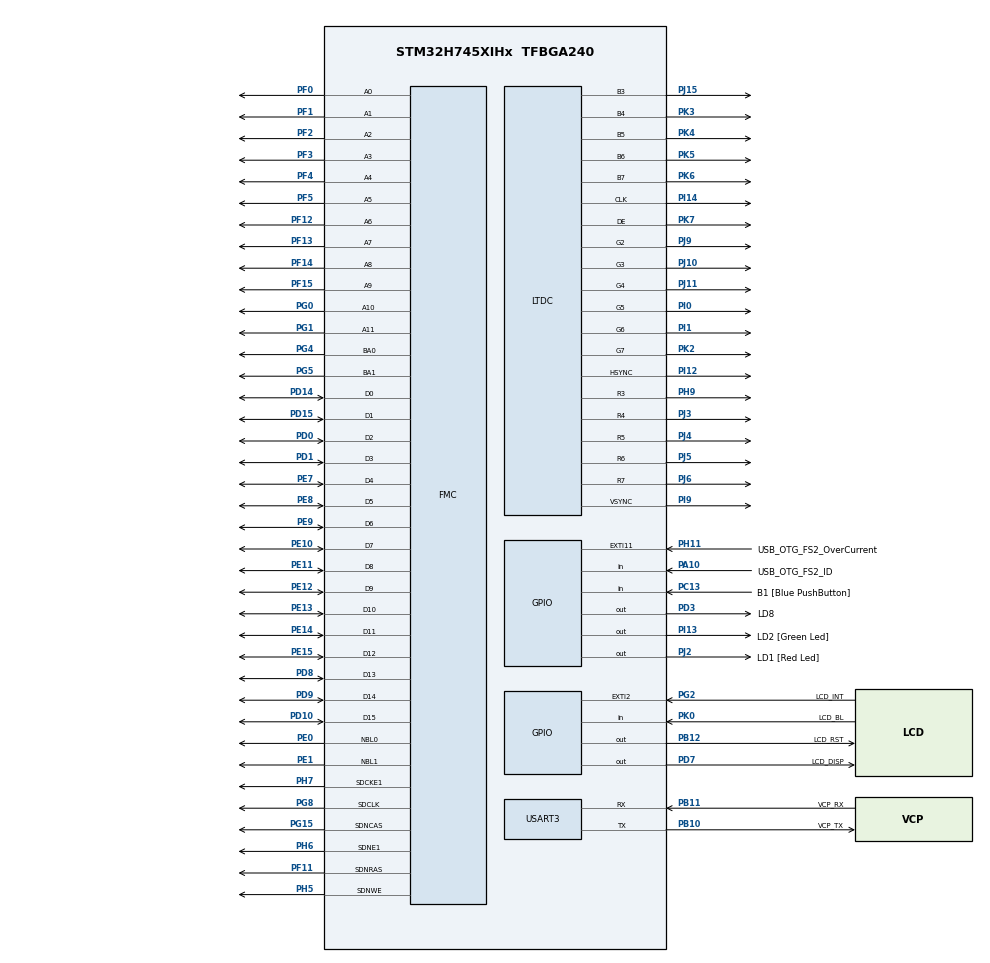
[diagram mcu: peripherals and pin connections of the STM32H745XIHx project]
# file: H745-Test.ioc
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Dma.USART3_RX.0.Polarity=HAL_DMAMUX_REQ_GEN_RISING
FMC.SDClockPeriod2=FMC_SDRAM_CLOCK_PERIOD_2
NVIC1.TimeBaseIP=TIM6
FMC.SDClockPeriod1=FMC_SDRAM_CLOCK_PERIOD_2
SH.FMC_A0.0=FMC_A0,12b-sda1
PH0-OSC_IN\ (PH0).PinAttribute=CortexM7
PI10.PinAttribute=CortexM4
PG8.Signal=FMC_SDCLK
PG0.Signal=FMC_A10
RCC.PLLFRACN=0
Dma.USART3_TX.1.PeriphDataAlignment=DMA_PDATAALIGN_BYTE
Dma.USART3_TX.1.Instance=DMA1_Stream1
SH.FMC_D5_DA5.0=FMC_D5,sd-16b-d1
PB8.PinAttribute=CortexM4
PB6.PinAttribute=CortexM4
SH.FMC_D9_DA9.0=FMC_D9,sd-16b-d1
VP_SYS_M4_VS_tim7.Mode=TIM7
CORTEX_M7.Enable-Cortex_Memory_Protection_Unit_Region0_Settings=MPU_REGION_ENABLE
Dma.USART3_RX.0.MemBurst=DMA_MBURST_SINGLE
PF7.Signal=QUADSPI_BK1_IO2
SH.FMC_SDNWE.0=FMC_SDNWE,12b-sda1
PH9.Signal=LTDC_R3
SH.FMC_D11_DA11.0=FMC_D11,sd-16b-d1
PJ5.Mode=RGB565
PB6.Signal=QUADSPI_BK1_NCS
PC7.Signal=SDMMC1_D7
PD0.Signal=FMC_D2_DA2
PD8.Signal=FMC_D13_DA13
PE1.Signal=FMC_NBL1
PC8.PinAttribute=CortexM4
Dma.USART3_TX.1.SignalID=NONE
PB12.GPIO_Label=LCD_RST
Dma.USART3_RX.0.FIFOThreshold=DMA_FIFO_THRESHOLD_FULL
FMC.SelfRefreshTime1=4
LTDC.PixelFormat_L0=LTDC_PIXEL_FORMAT_RGB565
LTDC.PixelFormat_L1=LTDC_PIXEL_FORMAT_RGB565
PC4.GPIO_Label=MII_RXD0
PE9.Signal=FMC_D6_DA6
SH.FMC_A2.0=FMC_A2,12b-sda1
PD8.PinAttribute=CortexM7
PB1.GPIO_Label=MII_RXD3
PI12.PinAttribute=CortexM7
CortexM7.Pins=PD7,PI13,PJ2
SH.FMC_D1_DA1.0=FMC_D1,sd-16b-d1
LTDC.HSync=41
VP_FREERTOS_M7_VS_CMSIS_V1.Mode=CMSIS_V1
Dma.USART3_TX.1.FIFOMode=DMA_FIFOMODE_DISABLE
PJ14.Signal=LTDC_B2
PA7.PinAttribute=CortexM4
Mcu.Package=TFBGA240
PB9.Signal=SDMMC1_D5
PB1.Signal=ETH_RXD3
VP_FREERTOS_M4_VS_CMSIS_V1.Mode=CMSIS_V1
RCC.PLL3FRACN=0
Dma.USART3_RX.0.PeriphBurst=DMA_PBURST_SINGLE
PA10.Signal=GPIO_Input
Dma.USART3_RX.0.SyncPolarity=HAL_DMAMUX_SYNC_NO_EVENT
FMC.WriteRecoveryTime1=3
PD7.PinAttribute=CortexM7
PC14-OSC32_IN\ (OSC32_IN).Mode=LSE-External-Oscillator
LTDC.VSync=10
FMC.RowCycleDelay2=7
FMC.RowCycleDelay1=7
PD15.Signal=FMC_D1_DA1
PG10.PinAttribute=CortexM4
PC7.PinAttribute=CortexM4
PG12.Signal=ETH_TXD1
PG12.PinAttribute=CortexM4
PK4.Signal=LTDC_B5
SH.FMC_A4.0=FMC_A4,12b-sda1
PH13.Signal=FDCAN1_TX
PA1.PinAttribute=CortexM4
PG5.Signal=FMC_A15_BA1
PC13.Signal=GPIO_Input
SH.FMC_D10_DA10.0=FMC_D10,sd-16b-d1
PD3.Signal=GPIO_Output
PC2.Signal=ETH_TXD2
PF9.PinAttribute=CortexM4
PI12.Signal=LTDC_HSYNC
PE8.PinAttribute=CortexM7
PA9.PinAttribute=CortexM4
RCC.PWR_Regulator_Voltage_Scale=PWR_REGULATOR_VOLTAGE_SCALE1
PG13.PinAttribute=CortexM4
LTDC.ImageWidth_L1=280
PJ11.Signal=LTDC_G4
LTDC.ImageWidth_L0=280
PD10.Signal=FMC_D15_DA15
PJ6.Mode=RGB565
PB8.GPIO_Label=SDIO1_D4
PJ3.Signal=LTDC_R4
PA2.PinAttribute=CortexM4
PH9.Mode=RGB565
PH11.GPIO_Label=USB_OTG_FS2_OverCurrent
Dma.USART3_RX.0.EventEnable=DISABLE
Dma.USART3_RX.0.SyncEnable=DISABLE
PD7.PinState=GPIO_PIN_RESET
PG11.PinAttribute=CortexM4
PB9.PinAttribute=CortexM4
PI7.Signal=SAI2_FS_A
PB1.PinAttribute=CortexM4
FMC.ReadBurst1=FMC_SDRAM_RBURST_ENABLE
SH.FMC_A6.0=FMC_A6,12b-sda1
FMC.ReadBurst2=FMC_SDRAM_RBURST_ENABLE
PE14.Signal=FMC_D11_DA11
LTDC.Blue_L0=0
PA1.GPIO_Label=MII_RX_CLK
PF13.Signal=FMC_A7
PC7.GPIO_Label=SDIO1_D7
PJ15.Mode=RGB565
PC14-OSC32_IN\ (OSC32_IN).GPIO_Label=OSC32_IN
PK4.Mode=RGB565
PC12.GPIO_Label=SDIO1_CK
PJ8.Signal=LTDC_G1
PE9.PinAttribute=CortexM7
ProjectManager.HeapSize=0x200
PH6.Signal=FMC_SDNE1
PD9.PinAttribute=CortexM7
NVIC1.DMA1_Stream0_IRQn=true\:5\:0\:false\:false\:true\:true\:false\:true
PD15.PinAttribute=CortexM7
PJ4.Mode=RGB565
PF4.Signal=FMC_A4
PC9.PinAttribute=CortexM4
Dma.USART3_TX.1.SyncRequestNumber=1
PD2.Signal=SDMMC1_CMD
PC1.PinAttribute=CortexM4
NVIC2.TIM7_IRQn=true\:0\:0\:false\:false\:true\:false\:false\:true
Mcu.Family=STM32H7
LTDC.BlendingFactor1_L1=LTDC_BLENDING_FACTOR1_PAxCA
LTDC.BlendingFactor1_L0=LTDC_BLENDING_FACTOR1_PAxCA
PD2.PinAttribute=CortexM4
PK3.Signal=LTDC_B4
Dma.USART3_RX.0.PeriphInc=DMA_PINC_DISABLE
SH.FMC_A8.0=FMC_A8,12b-sda1
PB10.PinAttribute=CortexM7
PH14.Signal=FDCAN1_RX
SH.FMC_D14_DA14.0=FMC_D14,sd-16b-d1
PH0-OSC_IN\ (PH0).Signal=RCC_OSC_IN
PG2.Signal=GPXTI2
Dma.USART3_TX.1.MemInc=DMA_MINC_ENABLE
PC15-OSC32_OUT\ (OSC32_OUT).Mode=LSE-External-Oscillator
RCC.PLL2FRACN=0
SH.FMC_A14_BA0.0=FMC_BA0,FourSdramBanks1
SH.FMC_A11.0=FMC_A11,12b-sda1
PB13.GPIO_Label=FDCAN2_TX
PC12.PinAttribute=CortexM4
PG11.Signal=ETH_TX_EN
PG15.Signal=FMC_SDNCAS
PG15.PinAttribute=CortexM7
Dma.USART3_TX.1.EventEnable=DISABLE
PJ2.Signal=GPIO_Output
PI9.PinAttribute=CortexM7
PJ2.PinState=GPIO_PIN_SET
LTDC.WindowX1_L1=480
SH.FMC_NBL1.0=FMC_NBL1,Sd2ByteEnable1
LTDC.WindowX1_L0=280
PI9.Mode=RGB565
PE15.PinAttribute=CortexM7
PK2.Mode=RGB565
PH1-OSC_OUT\ (PH1).Mode=HSE-External-Oscillator
FMC.ExitSelfRefreshDelay1=7
Dma.USART3_RX.0.SyncSignalID=NONE
PI14.Mode=RGB565
PB12.PinAttribute=Free
PA13\ (JTMS/SWDIO).PinAttribute=CortexM7
NVIC2.PriorityGroup=NVIC_PRIORITYGROUP_4
PF11.Signal=FMC_SDNRAS
PC11.GPIO_Label=SDIO1_D3
PD14.PinAttribute=CortexM7
LTDC.Red_L1=0
Dma.USART3_RX.0.FIFOMode=DMA_FIFOMODE_ENABLE
CortexM7.IPs=FATFS_M7\:I,FREERTOS_M7\:I,IWDG1\:I,RCC\:I,USB_DEVICE_M7\:I,USB_HOST_M7\:I,WWDG1\:I,DMA\:I,BDMA\:I,MDMA\:I,NVIC1\:I,CORTEX_M7\:I,DEBUG\:I,PDM2PCM_M7\:I,PWR\:I,RESMGR_UTILITY\:I,SYS\:I,OPENAMP_M7\:I,VREFBUF\:I,TIM6\:I,FMC\:I,USART3\:I,LTDC\:I
PD10.PinAttribute=CortexM7
PC10.PinAttribute=CortexM4
PF4.PinAttribute=CortexM7
PI1.Mode=RGB565
PB5.GPIO_Label=FDCAN2_RX
PC3.PinAttribute=CortexM4
Dma.Request1=USART3_TX
PE12.PinAttribute=CortexM7
PG11.GPIO_Label=MII_TX_EN
PD3.GPIO_Label=LD8
PC5.Signal=ETH_RXD1
PE7.Signal=FMC_D4_DA4
Dma.Request0=USART3_RX
PE2.GPIO_Label=MII_TXD3
PG2.GPIO_Label=LCD_INT
PH1-OSC_OUT\ (PH1).PinAttribute=CortexM7
PF15.PinAttribute=CortexM7
PH1-OSC_OUT\ (PH1).GPIO_Label=OSC_OUT
PK6.Signal=LTDC_B7
LTDC.WindowY1_L0=222
LTDC.WindowY1_L1=272
PH13.PinAttribute=CortexM4
PC9.GPIO_Label=SDIO1_D1
Dma.USART3_RX.0.SyncRequestNumber=1
PE10.PinAttribute=CortexM7
PC11.Signal=SDMMC1_D3
PI14.Signal=LTDC_CLK
PI15.PinAttribute=CortexM7
PC8.Signal=SDMMC1_D0
PD9.Signal=FMC_D14_DA14
PE7.PinAttribute=CortexM7
PA12.GPIO_Label=USB_OTG_FS2_P
PJ8.PinAttribute=CortexM7
PH1-OSC_OUT\ (PH1).Signal=RCC_OSC_OUT
PI7.PinAttribute=CortexM4
CORTEX_M7.MPU_Control=MPU_PRIVILEGED_DEFAULT
PI5.PinAttribute=CortexM4
PF10.PinAttribute=CortexM4
PF6.Signal=QUADSPI_BK1_IO3
PC15-OSC32_OUT\ (OSC32_OUT).Signal=RCC_OSC32_OUT
PB10.GPIO_Label=VCP_TX
PI13.PinAttribute=CortexM7
SH.FMC_D13_DA13.0=FMC_D13,sd-16b-d1
RCC.USBFreq_Value=61538461.538461536
PA1.Signal=ETH_RX_CLK
PK0.PinAttribute=Free
PK5.Mode=RGB565
board=STM32H745I-DISCO
PI9.Signal=LTDC_VSYNC
PG5.PinAttribute=CortexM7
PI13.GPIO_Label=LD2 [Green Led]
PK7.PinAttribute=CortexM7
PI4.Signal=SAI2_MCLK_A
NVIC1.CM4_SEV_IRQn=true\:5\:0\:false\:false\:true\:true\:true\:false
RCC.ADCFreq_Value=150000000
PC1.GPIO_Label=MII_MDC
SH.FMC_D12_DA12.0=FMC_D12,sd-16b-d1
PF1.Signal=FMC_A1
NVIC1.TimeBase=TIM6_DAC_IRQn
PJ13.PinAttribute=CortexM7
PJ0.Signal=LTDC_R1
PE0.Signal=FMC_NBL0
PE12.Signal=FMC_D9_DA9
PJ6.PinAttribute=CortexM7
Dma.USART3_RX.0.RequestNumber=1
RCC.SYSCLKFreq_VALUE=400000000
Dma.USART3_RX.0.Priority=DMA_PRIORITY_LOW
PE5.PinAttribute=CortexM4
PC15-OSC32_OUT\ (OSC32_OUT).GPIO_Label=OSC32_OUT
PJ5.Signal=LTDC_R6
PF6.PinAttribute=CortexM4
VP_PWR_V_PVD_IN.Mode=Mode_PVD_Int
PH0-OSC_IN\ (PH0).GPIO_Label=OSC_IN
PH3.Signal=ETH_COL
PC5.PinAttribute=CortexM4
CORTEX_M7.CPU_DCache=Enabled
PJ2.GPIO_Label=LD1 [Red Led]
PH6.PinAttribute=CortexM7
LTDC.ImageHeight_L0=222
LTDC.ImageHeight_L1=222
PB12.Signal=GPIO_Output
PJ13.Signal=LTDC_B1
CortexM4.IPs=FATFS_M4\:I,FREERTOS_M4\:I,IWDG2\:I,RCC,USB_DEVICE_M4\:I,USB_HOST_M4\:I,WWDG2\:I,DMA,BDMA,MDMA,NVIC2\:I,USART3,DEBUG,PDM2PCM_M4\:I,PWR,RESMGR_UTILITY,SYS_M4\:I,CORTEX_M4\:I,OPENAMP_M4\:I,VREFBUF,TIM7\:I
SH.FMC_D7_DA7.0=FMC_D7,sd-16b-d1
PK5.Signal=LTDC_B6
VP_SYS_VS_tim6.Mode=TIM6
PJ9.Mode=RGB565
PD3.PinState=GPIO_PIN_SET
FMC.RCDDelay1=2
PK5.PinAttribute=CortexM7
PB10.Mode=Asynchronous
PG4.Signal=FMC_A14_BA0
PC12.Signal=SDMMC1_CK
FMC.LoadToActiveDelay1=2
PJ4.PinAttribute=CortexM7
PC6.GPIO_Label=SDIO1_D6
PJ3.PinAttribute=CortexM7
PJ11.PinAttribute=CortexM7
PJ12.PinAttribute=CortexM7
Dma.USART3_TX.1.RequestNumber=1
PB13.Signal=FDCAN2_TX
PG13.Signal=ETH_TXD0
RCC.SYSCLKSource=RCC_SYSCLKSOURCE_PLLCLK
PJ10.Signal=LTDC_G3
PI1.PinAttribute=CortexM7
SH.FMC_A15_BA1.0=FMC_BA1,FourSdramBanks1
USART3.VirtualMode-Asynchronous=VM_ASYNC
PA14\ (JTCK/SWCLK).Signal=DEBUG_JTCK-SWCLK
PK6.PinAttribute=CortexM7
PH5.Signal=FMC_SDNWE
PK4.PinAttribute=CortexM7
PI13.PinState=GPIO_PIN_SET
PC3.Signal=ETH_TX_CLK
PE5.Signal=SAI4_CK2
RCC.DIVM3=5
RCC.DIVM2=5
PI4.PinAttribute=CortexM4
RCC.DIVM1=5
PK7.Mode=RGB565
PI6.Signal=SAI2_SD_A
PE2.Signal=ETH_TXD3
PA14\ (JTCK/SWCLK).Mode=Serial_Wire
PJ1.PinAttribute=CortexM7
PJ10.PinAttribute=CortexM7
PF3.Signal=FMC_A3
PJ14.PinAttribute=CortexM7
PJ5.PinAttribute=CortexM7
PE10.Signal=FMC_D7_DA7
RCC.SAI23CLockSelection=RCC_SAI23CLKSOURCE_PLL2
Dma.USART3_TX.1.Priority=DMA_PRIORITY_LOW
PI0.PinAttribute=CortexM7
FREERTOS_M4.Tasks01=defaultTask,0,128,StartDefaultTask,Default,NULL,Dynamic,NULL,NULL
LTDC.Green=127
PJ4.Signal=LTDC_R5
PF0.PinAttribute=CortexM7
SH.FMC_A1.0=FMC_A1,12b-sda1
PH2.Signal=ETH_CRS
SH.FMC_SDCLK.0=FMC_SDCLK,12b-sda1
RCC.APB4Freq_Value=100000000
FREERTOS_M7.Tasks01=defaultTask,0,128,StartDefaultTask,Default,NULL,Dynamic,NULL,NULL
PF14.Signal=FMC_A8
RCC.FDCANCLockSelection=RCC_FDCANCLKSOURCE_PLL2
Dma.USART3_TX.1.PeriphInc=DMA_PINC_DISABLE
PH0-OSC_IN\ (PH0).Mode=HSE-External-Oscillator
SH.FMC_D3_DA3.0=FMC_D3,sd-16b-d1
RCC.SupplySource=PWR_DIRECT_SMPS_SUPPLY
PG0.PinAttribute=CortexM7
PI10.GPIO_Label=MII_RX_ER
Dma.USART3_RX.0.Instance=DMA1_Stream0
Dma.USART3_TX.1.MemDataAlignment=DMA_MDATAALIGN_BYTE
RCC.DIVQ3=13
RCC.DIVQ2=6
RCC.DIVQ1=4
PF1.PinAttribute=CortexM7
Dma.USART3_TX.1.SyncSignalID=NONE
PA9.GPIO_Label=VBUS_FS2
CORTEX_M7.IsCacheable-Cortex_Memory_Protection_Unit_Region0_Settings=MPU_ACCESS_CACHEABLE
PC6.Signal=SDMMC1_D6
PB11.GPIO_Label=VCP_RX
PE0.PinAttribute=CortexM7
PD7.Signal=GPIO_Output
PD1.Signal=FMC_D3_DA3
PA11.GPIO_Label=USB_OTG_FS2_N
RCC.DIVP2=4
PG13.GPIO_Label=MII_TXD0
PJ15.PinAttribute=CortexM7
PG10.Signal=SAI2_SD_B
SH.FMC_A3.0=FMC_A3,12b-sda1
PJ7.Signal=LTDC_G0
PK2.PinAttribute=CortexM7
PA12.PinAttribute=CortexM4
FMC.CASLatency1=FMC_SDRAM_CAS_LATENCY_3
PB11.Mode=Asynchronous
SH.FMC_D15_DA15.0=FMC_D15,sd-16b-d1
PA9.Signal=USB_OTG_FS_VBUS
RCC.DIVN3=160
RCC.DIVN2=120
RCC.DIVN1=160
PH3.PinAttribute=CortexM4
CORTEX_M7.BaseAddress-Cortex_Memory_Protection_Unit_Region0_Settings=0xD0000000
PF12.PinAttribute=CortexM7
PB10.Signal=USART3_TX
RCC.USBCLockSelection=RCC_USBCLKSOURCE_PLL3
PJ15.Signal=LTDC_B3
PG1.PinAttribute=CortexM7
PH6.Mode=SdramChipSelect2_1
PK3.PinAttribute=CortexM7
PH11.PinAttribute=Free
PE15.Signal=FMC_D12_DA12
PA11.PinAttribute=CortexM4
PE8.Signal=FMC_D5_DA5
PI1.Signal=LTDC_G6
PH2.PinAttribute=CortexM4
CORTEX_M7.AccessPermission-Cortex_Memory_Protection_Unit_Region0_Settings=MPU_REGION_FULL_ACCESS
PE1.PinAttribute=CortexM7
SH.FMC_SDNCAS.0=FMC_SDNCAS,12b-sda1
PJ2.PinAttribute=CortexM7
PE2.PinAttribute=CortexM4
PH14.GPIO_Label=FDCAN2_RX
PB5.Signal=FDCAN2_RX
PD11.Signal=QUADSPI_BK1_IO0
LTDC.Alpha_L1=223
SH.FMC_A5.0=FMC_A5,12b-sda1
LTDC.Alpha_L0=255
PA11.Signal=USB_OTG_FS_DM
PD1.PinAttribute=CortexM7
Dma.USART3_TX.1.SyncPolarity=HAL_DMAMUX_SYNC_NO_EVENT
PF2.PinAttribute=CortexM7
PF9.Signal=QUADSPI_BK1_IO1
PJ10.Mode=RGB565
PA14\ (JTCK/SWCLK).PinAttribute=CortexM7
PC3.GPIO_Label=MII_TX_CLK
PE14.PinAttribute=CortexM7
RCC.DIVR3=83
PB0.Signal=ETH_RXD2
PC1.Signal=ETH_MDC
PF13.PinAttribute=CortexM7
PD2.GPIO_Label=SDIO1_CMD
PH2.GPIO_Label=MII_CRS
LTDC.Alpha0_L0=0
PA13\ (JTMS/SWDIO).Signal=DEBUG_JTMS-SWDIO
LTDC.Alpha0_L1=0
PI12.Mode=RGB565
PG2.PinAttribute=Free
PK7.Signal=LTDC_DE
RCC.CortexFreq_Value=400000000
PF5.PinAttribute=CortexM7
RCC.HPRE=RCC_HCLK_DIV2
LTDC.HBP=13
PC10.Signal=SDMMC1_D2
SH.FMC_NBL0.0=FMC_NBL0,Sd2ByteEnable1
SH.FMC_D6_DA6.0=FMC_D6,sd-16b-d1
PB0.GPIO_Label=MII_RXD2
PC13.GPIO_Label=B1 [Blue PushButton]
PB11.Signal=USART3_RX
PC11.PinAttribute=CortexM4
PE4.PinAttribute=CortexM4
ProjectManager.StackSize=0x400
NVIC2.TimeBase=TIM7_IRQn
PJ6.Signal=LTDC_R7
PB11.PinAttribute=CortexM7
SH.FMC_A7.0=FMC_A7,12b-sda1
PA12.Signal=USB_OTG_FS_DP
PA10.PinAttribute=Free
RCC.HCLKFreq_Value=200000000
PH7.PinAttribute=CortexM7
PH9.PinAttribute=CortexM7
PF12.Signal=FMC_A6
PE13.PinAttribute=CortexM7
PI13.Signal=GPIO_Output
PC2.PinAttribute=CortexM4
SH.FMC_A10.0=FMC_A10,12b-sda1
PF14.PinAttribute=CortexM7
PB0.PinAttribute=CortexM4
Dma.USART3_RX.0.MemDataAlignment=DMA_MDATAALIGN_BYTE
SH.FMC_D8_DA8.0=FMC_D8,sd-16b-d1
Dma.USART3_TX.1.Mode=DMA_NORMAL
FMC.RPDelay2=2
FMC.RPDelay1=2
NVIC1.LTDC_IRQn=true\:5\:0\:false\:false\:true\:true\:true\:true
SH.FMC_D2_DA2.0=FMC_D2,sd-16b-d1
PD0.PinAttribute=CortexM7
PE13.Signal=FMC_D10_DA10
PF3.PinAttribute=CortexM7
PI5.Signal=SAI2_SCK_A
PK6.Mode=RGB565
PI0.Signal=LTDC_G5
PA10.GPIO_Label=USB_OTG_FS2_ID
Dma.USART3_RX.0.PeriphDataAlignment=DMA_PDATAALIGN_BYTE
LTDC.HFP=32
LTDC.BlendingFactor2_L0=LTDC_BLENDING_FACTOR2_PAxCA
LTDC.BlendingFactor2_L1=LTDC_BLENDING_FACTOR2_PAxCA
NVIC2.TimeBaseIP=TIM7
SH.FMC_SDNRAS.0=FMC_SDNRAS,12b-sda1
PF7.PinAttribute=CortexM4
LTDC.ActiveW=480
PE4.Signal=SAI4_D2
PD7.GPIO_Label=LCD_DISP
PH7.Mode=SdramChipSelect2_1
RCC.APB3Freq_Value=100000000
Dma.USART3_RX.0.Direction=DMA_PERIPH_TO_MEMORY
PJ9.PinAttribute=CortexM7
PJ9.Signal=LTDC_G2
SH.FMC_D0_DA0.0=FMC_D0,sd-16b-d1
RCC.D1PPRE=RCC_APB3_DIV2
PJ12.Signal=LTDC_B0
PD3.PinAttribute=CortexM4
PK0.GPIO_Label=LCD_BL
PA2.GPIO_Label=MII_MDIO
PG8.PinAttribute=CortexM7
SH.FMC_A9.0=FMC_A9,12b-sda1
PJ1.Signal=LTDC_R2
SH.FMC_D4_DA4.0=FMC_D4,sd-16b-d1
Dma.USART3_RX.0.MemInc=DMA_MINC_ENABLE
PF5.Signal=FMC_A5
PH3.GPIO_Label=MII_COL
PH7.Signal=FMC_SDCKE1
PF0.Signal=FMC_A0
PF11.PinAttribute=CortexM7
PC2.GPIO_Label=MII_TXD2
PG4.PinAttribute=CortexM7
RCC.PLLSourceVirtual=RCC_PLLSOURCE_HSE
PI6.PinAttribute=CortexM4
PK2.Signal=LTDC_G7
LTDC.FBStartAdress_L0=0
CORTEX_M7.CPU_ICache=Enabled
LTDC.FBStartAdress_L1=0
NVIC1.TIM6_DAC_IRQn=true\:0\:0\:false\:false\:true\:false\:false\:true
PA13\ (JTMS/SWDIO).Mode=Serial_Wire
PB9.GPIO_Label=SDIO1_D5
PC10.GPIO_Label=SDIO1_D2
PH11.Signal=GPXTI11
NVIC1.RCC_IRQn=true\:5\:0\:false\:false\:true\:true\:true\:false
PG1.Signal=FMC_A11
CortexM4.Pins=PD3
PJ0.PinAttribute=CortexM7
PI14.PinAttribute=CortexM7
PC4.Signal=ETH_RXD0
NVIC1.PriorityGroup=NVIC_PRIORITYGROUP_4
RCC.D2PPRE2=RCC_APB2_DIV2
RCC.D2PPRE1=RCC_APB1_DIV2
PI10.Signal=ETH_RX_ER
PJ7.PinAttribute=CortexM7
Dma.USART3_RX.0.Mode=DMA_CIRCULAR
PJ11.Mode=RGB565
PB13.PinAttribute=CortexM4
NVIC1.DMA1_Stream1_IRQn=true\:5\:0\:false\:false\:true\:true\:false\:true
PH13.GPIO_Label=FDCAN1_TX
PC8.GPIO_Label=SDIO1_D0
NVIC1.FMC_IRQn=true\:5\:0\:false\:false\:true\:true\:true\:true
ProjectManager.TargetToolchain=STM32CubeIDE
PH14.PinAttribute=CortexM4
LTDC.ActiveH=272
PE11.PinAttribute=CortexM7
PC14-OSC32_IN\ (OSC32_IN).PinAttribute=CortexM7
PI0.Mode=RGB565
PH5.PinAttribute=CortexM7
PF2.Signal=FMC_A2
PC4.PinAttribute=CortexM4
PE11.Signal=FMC_D8_DA8
PK0.Signal=GPIO_Input
NVIC1.USART3_IRQn=true\:5\:0\:false\:false\:true\:true\:true\:true
PC6.PinAttribute=CortexM4
PB5.PinAttribute=CortexM4
PJ3.Mode=RGB565
RCC.APB2Freq_Value=100000000
PF10.Signal=QUADSPI_CLK
PF15.Signal=FMC_A9
PD11.PinAttribute=CortexM4
Mcu.Name=STM32H745XIHx
CORTEX_M7.Size-Cortex_Memory_Protection_Unit_Region0_Settings=MPU_REGION_SIZE_32MB
PA2.Signal=ETH_MDIO
Dma.USART3_TX.1.SyncEnable=DISABLE
PC13.PinAttribute=Free
LTDC.WindowY0_L1=50
PD14.Signal=FMC_D0_DA0
PA7.GPIO_Label=MII_RX_DV
LTDC.WindowX0_L1=200
PC14-OSC32_IN\ (OSC32_IN).Signal=RCC_OSC32_IN
PC5.GPIO_Label=MII_RXD1
Dma.USART3_RX.0.SignalID=NONE
PG12.GPIO_Label=MII_TXD1
Dma.USART3_TX.1.Polarity=HAL_DMAMUX_REQ_GEN_RISING
NVIC2.CM7_SEV_IRQn=true\:5\:0\:false\:false\:true\:true\:true\:false
PK3.Mode=RGB565
Dma.USART3_TX.1.Direction=DMA_MEMORY_TO_PERIPH
PI15.Signal=LTDC_R0
PC15-OSC32_OUT\ (OSC32_OUT).PinAttribute=CortexM7
PB8.Signal=SDMMC1_D4
RCC.D3PPRE=RCC_APB4_DIV2
PC9.Signal=SDMMC1_D1
RCC.APB1Freq_Value=100000000
PA7.Signal=ETH_RX_DV

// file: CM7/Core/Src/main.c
/* USER CODE BEGIN Header */
/**
  ******************************************************************************
  * @file           : main.c
  * @brief          : Main program body
  ******************************************************************************
  * @attention
  *
  * <h2><center>&copy; Copyright (c) 2021 STMicroelectronics.
  * All rights reserved.</center></h2>
  *
  * This software component is licensed by ST under BSD 3-Clause license,
  * the "License"; You may not use this file except in compliance with the
  * License. You may obtain a copy of the License at:
  *                        opensource.org/licenses/BSD-3-Clause
  *
  ******************************************************************************
  */
/* USER CODE END Header */
#include "main.h"
#include "cmsis_os.h"

/* USER CODE BEGIN Includes */
#include "HelloWorld.h"
/* USER CODE END Includes */

/* USER CODE BEGIN PD */

#ifndef HSEM_ID_0
#define HSEM_ID_0 (0U) /* HW semaphore 0*/
#endif
/* USER CODE END PD */

LTDC_HandleTypeDef hltdc;

UART_HandleTypeDef huart3;
DMA_HandleTypeDef hdma_usart3_rx;
DMA_HandleTypeDef hdma_usart3_tx;

SDRAM_HandleTypeDef hsdram1;

osThreadId defaultTaskHandle;
/* USER CODE BEGIN PV */
__IO uint32_t ReloadFlag = 0;
/* Pictures position */
uint32_t Xpos1 = 0;
uint32_t Xpos2 = 200;
uint32_t Ypos1 = 0;
uint32_t Ypos2 = 50;
/* USER CODE END PV */

void SystemClock_Config(void);
static void MPU_Config(void);
static void MX_GPIO_Init(void);
static void MX_DMA_Init(void);
static void MX_FMC_Init(void);
static void MX_USART3_UART_Init(void);
static void MX_LTDC_Init(void);
void StartDefaultTask(void const * argument);

int main(void)
{
/* USER CODE BEGIN Boot_Mode_Sequence_0 */
  int32_t timeout;
/* USER CODE END Boot_Mode_Sequence_0 */

  /* MPU Configuration--------------------------------------------------------*/
  MPU_Config();

  /* Enable I-Cache---------------------------------------------------------*/
  SCB_EnableICache();

  /* Enable D-Cache---------------------------------------------------------*/
  SCB_EnableDCache();

/* USER CODE BEGIN Boot_Mode_Sequence_1 */
  /* Wait until CPU2 boots and enters in stop mode or timeout*/
  timeout = 0xFFFF;
  while((__HAL_RCC_GET_FLAG(RCC_FLAG_D2CKRDY) != RESET) && (timeout-- > 0));
  if ( timeout < 0 )
  {
  Error_Handler();
  }
/* USER CODE END Boot_Mode_Sequence_1 */
  /* MCU Configuration--------------------------------------------------------*/

  /* Reset of all peripherals, Initializes the Flash interface and the Systick. */
  HAL_Init();

  /* Configure the system clock */
  SystemClock_Config();
/* USER CODE BEGIN Boot_Mode_Sequence_2 */
/* When system initialization is finished, Cortex-M7 will release Cortex-M4 by means of
HSEM notification */
/*HW semaphore Clock enable*/
__HAL_RCC_HSEM_CLK_ENABLE();
/*Take HSEM */
HAL_HSEM_FastTake(HSEM_ID_0);
/*Release HSEM in order to notify the CPU2(CM4)*/
HAL_HSEM_Release(HSEM_ID_0,0);
/* wait until CPU2 wakes up from stop mode */
timeout = 0xFFFF;
while((__HAL_RCC_GET_FLAG(RCC_FLAG_D2CKRDY) == RESET) && (timeout-- > 0));
if ( timeout < 0 )
{
Error_Handler();
}
/* USER CODE END Boot_Mode_Sequence_2 */

  /* Initialize all configured peripherals */
  MX_GPIO_Init();
  MX_DMA_Init();
  MX_FMC_Init();
  MX_USART3_UART_Init();
  MX_LTDC_Init();

  /* Create the thread(s) */
  /* definition and creation of defaultTask */
  osThreadDef(defaultTask, StartDefaultTask, osPriorityNormal, 0, 128);
  defaultTaskHandle = osThreadCreate(osThread(defaultTask), NULL);

  /* Start scheduler */
  osKernelStart();

  /* We should never get here as control is now taken by the scheduler */
  /* Infinite loop */
  while (1)
  {

  }
}

void SystemClock_Config(void)
{
  RCC_OscInitTypeDef RCC_OscInitStruct = {0};
  RCC_ClkInitTypeDef RCC_ClkInitStruct = {0};

  /** Supply configuration update enable
  */
  HAL_PWREx_ConfigSupply(PWR_DIRECT_SMPS_SUPPLY);
  /** Configure the main internal regulator output voltage
  */
  __HAL_PWR_VOLTAGESCALING_CONFIG(PWR_REGULATOR_VOLTAGE_SCALE1);

  while(!__HAL_PWR_GET_FLAG(PWR_FLAG_VOSRDY)) {}
  /** Macro to configure the PLL clock source
  */
  __HAL_RCC_PLL_PLLSOURCE_CONFIG(RCC_PLLSOURCE_HSE);
  /** Initializes the RCC Oscillators according to the specified parameters
  * in the RCC_OscInitTypeDef structure.
  */
  RCC_OscInitStruct.OscillatorType = RCC_OSCILLATORTYPE_HSE;
  RCC_OscInitStruct.HSEState = RCC_HSE_ON;
  RCC_OscInitStruct.PLL.PLLState = RCC_PLL_ON;
  RCC_OscInitStruct.PLL.PLLSource = RCC_PLLSOURCE_HSE;
  RCC_OscInitStruct.PLL.PLLM = 5;
  RCC_OscInitStruct.PLL.PLLN = 160;
  RCC_OscInitStruct.PLL.PLLP = 2;
  RCC_OscInitStruct.PLL.PLLQ = 4;
  RCC_OscInitStruct.PLL.PLLR = 2;
  RCC_OscInitStruct.PLL.PLLRGE = RCC_PLL1VCIRANGE_2;
  RCC_OscInitStruct.PLL.PLLVCOSEL = RCC_PLL1VCOWIDE;
  RCC_OscInitStruct.PLL.PLLFRACN = 0;
  if (HAL_RCC_OscConfig(&RCC_OscInitStruct) != HAL_OK)
  {
    Error_Handler();
  }
  /** Initializes the CPU, AHB and APB buses clocks
  */
  RCC_ClkInitStruct.ClockType = RCC_CLOCKTYPE_HCLK|RCC_CLOCKTYPE_SYSCLK
                              |RCC_CLOCKTYPE_PCLK1|RCC_CLOCKTYPE_PCLK2
                              |RCC_CLOCKTYPE_D3PCLK1|RCC_CLOCKTYPE_D1PCLK1;
  RCC_ClkInitStruct.SYSCLKSource = RCC_SYSCLKSOURCE_PLLCLK;
  RCC_ClkInitStruct.SYSCLKDivider = RCC_SYSCLK_DIV1;
  RCC_ClkInitStruct.AHBCLKDivider = RCC_HCLK_DIV2;
  RCC_ClkInitStruct.APB3CLKDivider = RCC_APB3_DIV2;
  RCC_ClkInitStruct.APB1CLKDivider = RCC_APB1_DIV2;
  RCC_ClkInitStruct.APB2CLKDivider = RCC_APB2_DIV2;
  RCC_ClkInitStruct.APB4CLKDivider = RCC_APB4_DIV2;

  if (HAL_RCC_ClockConfig(&RCC_ClkInitStruct, FLASH_LATENCY_2) != HAL_OK)
  {
    Error_Handler();
  }
}

static void MX_LTDC_Init(void)
{

  LTDC_LayerCfgTypeDef pLayerCfg = {0};
  LTDC_LayerCfgTypeDef pLayerCfg1 = {0};

  hltdc.Instance = LTDC;
  hltdc.Init.HSPolarity = LTDC_HSPOLARITY_AL;
  hltdc.Init.VSPolarity = LTDC_VSPOLARITY_AL;
  hltdc.Init.DEPolarity = LTDC_DEPOLARITY_AL;
  hltdc.Init.PCPolarity = LTDC_PCPOLARITY_IPC;
  hltdc.Init.HorizontalSync = 40;
  hltdc.Init.VerticalSync = 9;
  hltdc.Init.AccumulatedHBP = 53;
  hltdc.Init.AccumulatedVBP = 11;
  hltdc.Init.AccumulatedActiveW = 533;
  hltdc.Init.AccumulatedActiveH = 283;
  hltdc.Init.TotalWidth = 565;
  hltdc.Init.TotalHeigh = 285;
  hltdc.Init.Backcolor.Blue = 0;
  hltdc.Init.Backcolor.Green = 127;
  hltdc.Init.Backcolor.Red = 0;
  if (HAL_LTDC_Init(&hltdc) != HAL_OK)
  {
    Error_Handler();
  }
  pLayerCfg.WindowX0 = 0;
  pLayerCfg.WindowX1 = 280;
  pLayerCfg.WindowY0 = 0;
  pLayerCfg.WindowY1 = 222;
  pLayerCfg.PixelFormat = LTDC_PIXEL_FORMAT_RGB565;
  pLayerCfg.Alpha = 255;
  pLayerCfg.Alpha0 = 0;
  pLayerCfg.BlendingFactor1 = LTDC_BLENDING_FACTOR1_PAxCA;
  pLayerCfg.BlendingFactor2 = LTDC_BLENDING_FACTOR2_PAxCA;
  pLayerCfg.FBStartAdress = 0;
  pLayerCfg.ImageWidth = 280;
  pLayerCfg.ImageHeight = 222;
  pLayerCfg.Backcolor.Blue = 0;
  pLayerCfg.Backcolor.Green = 0;
  pLayerCfg.Backcolor.Red = 0;
  if (HAL_LTDC_ConfigLayer(&hltdc, &pLayerCfg, 0) != HAL_OK)
  {
    Error_Handler();
  }
  pLayerCfg1.WindowX0 = 200;
  pLayerCfg1.WindowX1 = 480;
  pLayerCfg1.WindowY0 = 50;
  pLayerCfg1.WindowY1 = 272;
  pLayerCfg1.PixelFormat = LTDC_PIXEL_FORMAT_RGB565;
  pLayerCfg1.Alpha = 223;
  pLayerCfg1.Alpha0 = 0;
  pLayerCfg1.BlendingFactor1 = LTDC_BLENDING_FACTOR1_PAxCA;
  pLayerCfg1.BlendingFactor2 = LTDC_BLENDING_FACTOR2_PAxCA;
  pLayerCfg1.FBStartAdress = 0;
  pLayerCfg1.ImageWidth = 280;
  pLayerCfg1.ImageHeight = 222;
  pLayerCfg1.Backcolor.Blue = 0;
  pLayerCfg1.Backcolor.Green = 0;
  pLayerCfg1.Backcolor.Red = 0;
  if (HAL_LTDC_ConfigLayer(&hltdc, &pLayerCfg1, 1) != HAL_OK)
  {
    Error_Handler();
  }
  /* USER CODE BEGIN LTDC_Init 2 */
  HAL_LTDC_SetAddress(&hltdc, (uint32_t) &logo_image.pixel_data, 0);
  HAL_LTDC_SetAddress(&hltdc, (uint32_t) &logo_image.pixel_data, 1);
  /* USER CODE END LTDC_Init 2 */

}

static void MX_USART3_UART_Init(void)
{

  huart3.Instance = USART3;
  huart3.Init.BaudRate = 115200;
  huart3.Init.WordLength = UART_WORDLENGTH_8B;
  huart3.Init.StopBits = UART_STOPBITS_1;
  huart3.Init.Parity = UART_PARITY_NONE;
  huart3.Init.Mode = UART_MODE_TX_RX;
  huart3.Init.HwFlowCtl = UART_HWCONTROL_NONE;
  huart3.Init.OverSampling = UART_OVERSAMPLING_16;
  huart3.Init.OneBitSampling = UART_ONE_BIT_SAMPLE_DISABLE;
  huart3.Init.ClockPrescaler = UART_PRESCALER_DIV1;
  huart3.AdvancedInit.AdvFeatureInit = UART_ADVFEATURE_NO_INIT;
  if (HAL_UART_Init(&huart3) != HAL_OK)
  {
    Error_Handler();
  }
  if (HAL_UARTEx_SetTxFifoThreshold(&huart3, UART_TXFIFO_THRESHOLD_1_8) != HAL_OK)
  {
    Error_Handler();
  }
  if (HAL_UARTEx_SetRxFifoThreshold(&huart3, UART_RXFIFO_THRESHOLD_1_8) != HAL_OK)
  {
    Error_Handler();
  }
  if (HAL_UARTEx_DisableFifoMode(&huart3) != HAL_OK)
  {
    Error_Handler();
  }

}

static void MX_DMA_Init(void)
{

  /* DMA controller clock enable */
  __HAL_RCC_DMA1_CLK_ENABLE();

  /* DMA interrupt init */
  /* DMA1_Stream0_IRQn interrupt configuration */
  HAL_NVIC_SetPriority(DMA1_Stream0_IRQn, 5, 0);
  HAL_NVIC_EnableIRQ(DMA1_Stream0_IRQn);
  /* DMA1_Stream1_IRQn interrupt configuration */
  HAL_NVIC_SetPriority(DMA1_Stream1_IRQn, 5, 0);
  HAL_NVIC_EnableIRQ(DMA1_Stream1_IRQn);

}

/* FMC initialization function */
void MX_FMC_Init(void)
{

  FMC_SDRAM_TimingTypeDef SdramTiming = {0};

  /** Perform the SDRAM1 memory initialization sequence
  */
  hsdram1.Instance = FMC_SDRAM_DEVICE;
  /* hsdram1.Init */
  hsdram1.Init.SDBank = FMC_SDRAM_BANK2;
  hsdram1.Init.ColumnBitsNumber = FMC_SDRAM_COLUMN_BITS_NUM_8;
  hsdram1.Init.RowBitsNumber = FMC_SDRAM_ROW_BITS_NUM_12;
  hsdram1.Init.MemoryDataWidth = FMC_SDRAM_MEM_BUS_WIDTH_16;
  hsdram1.Init.InternalBankNumber = FMC_SDRAM_INTERN_BANKS_NUM_4;
  hsdram1.Init.CASLatency = FMC_SDRAM_CAS_LATENCY_3;
  hsdram1.Init.WriteProtection = FMC_SDRAM_WRITE_PROTECTION_DISABLE;
  hsdram1.Init.SDClockPeriod = FMC_SDRAM_CLOCK_PERIOD_2;
  hsdram1.Init.ReadBurst = FMC_SDRAM_RBURST_ENABLE;
  hsdram1.Init.ReadPipeDelay = FMC_SDRAM_RPIPE_DELAY_0;
  /* SdramTiming */
  SdramTiming.LoadToActiveDelay = 2;
  SdramTiming.ExitSelfRefreshDelay = 7;
  SdramTiming.SelfRefreshTime = 4;
  SdramTiming.RowCycleDelay = 7;
  SdramTiming.WriteRecoveryTime = 3;
  SdramTiming.RPDelay = 2;
  SdramTiming.RCDDelay = 2;

  if (HAL_SDRAM_Init(&hsdram1, &SdramTiming) != HAL_OK)
  {
    Error_Handler( );
  }

}

static void MX_GPIO_Init(void)
{
  GPIO_InitTypeDef GPIO_InitStruct = {0};

  /* GPIO Ports Clock Enable */
  __HAL_RCC_GPIOK_CLK_ENABLE();
  __HAL_RCC_GPIOI_CLK_ENABLE();
  __HAL_RCC_GPIOE_CLK_ENABLE();
  __HAL_RCC_GPIOJ_CLK_ENABLE();
  __HAL_RCC_GPIOA_CLK_ENABLE();
  __HAL_RCC_GPIOC_CLK_ENABLE();
  __HAL_RCC_GPIOD_CLK_ENABLE();
  __HAL_RCC_GPIOG_CLK_ENABLE();
  __HAL_RCC_GPIOF_CLK_ENABLE();
  __HAL_RCC_GPIOH_CLK_ENABLE();
  __HAL_RCC_GPIOB_CLK_ENABLE();

  /*Configure GPIO pin Output Level */
  HAL_GPIO_WritePin(LCD_DISP_GPIO_Port, LCD_DISP_Pin, GPIO_PIN_RESET);

  /*Configure GPIO pin Output Level */
  HAL_GPIO_WritePin(LD2_GPIO_Port, LD2_Pin, GPIO_PIN_SET);

  /*Configure GPIO pin Output Level */
  HAL_GPIO_WritePin(LD1_GPIO_Port, LD1_Pin, GPIO_PIN_SET);

  /*Configure GPIO pin : LCD_DISP_Pin */
  GPIO_InitStruct.Pin = LCD_DISP_Pin;
  GPIO_InitStruct.Mode = GPIO_MODE_OUTPUT_PP;
  GPIO_InitStruct.Pull = GPIO_NOPULL;
  GPIO_InitStruct.Speed = GPIO_SPEED_FREQ_LOW;
  HAL_GPIO_Init(LCD_DISP_GPIO_Port, &GPIO_InitStruct);

  /*Configure GPIO pin : LD2_Pin */
  GPIO_InitStruct.Pin = LD2_Pin;
  GPIO_InitStruct.Mode = GPIO_MODE_OUTPUT_PP;
  GPIO_InitStruct.Pull = GPIO_NOPULL;
  GPIO_InitStruct.Speed = GPIO_SPEED_FREQ_LOW;
  HAL_GPIO_Init(LD2_GPIO_Port, &GPIO_InitStruct);

  /*Configure GPIO pin : LD1_Pin */
  GPIO_InitStruct.Pin = LD1_Pin;
  GPIO_InitStruct.Mode = GPIO_MODE_OUTPUT_PP;
  GPIO_InitStruct.Pull = GPIO_NOPULL;
  GPIO_InitStruct.Speed = GPIO_SPEED_FREQ_LOW;
  HAL_GPIO_Init(LD1_GPIO_Port, &GPIO_InitStruct);

}

/* USER CODE BEGIN 4 */
/**
  * @brief  calculate pictures position.
  * @param  x1:    picture1 x position
  * @param  y1:    picture1 y position
  * @param  x2:    picture2 x position
  * @param  y2:    picture2 y position
  * @param  index:
  * @retval None
  */
static void PicturesPosition(uint32_t* x1, uint32_t* y1, uint32_t* x2, uint32_t* y2, uint32_t index)
{
  /* picture1 position */
  *x1 = index*4;
  *y1 = index;

  /* picture2 position */
  *x2 = 200 - index*4;
  *y2 = 50 - index;
}

/**
  * @brief  Reload Event callback.
  * @param  hltdc: pointer to a LTDC_HandleTypeDef structure that contains
  *                the configuration information for the LTDC.
  * @retval None
  */
void HAL_LTDC_ReloadEventCallback(LTDC_HandleTypeDef *hltdc)
{
  ReloadFlag = 1;
}
/* USER CODE END 4 */

void StartDefaultTask(void const * argument)
{
  /* USER CODE BEGIN 5 */
	uint32_t index = 0;
  /* Infinite loop */
  for(;;)
  {
  	HAL_GPIO_TogglePin(LD1_GPIO_Port, LD1_Pin);
    for (index = 0; index < 50; index++)
    {
      /* calculate new picture position */
       PicturesPosition(&Xpos1, &Ypos1, &Xpos2, &Ypos2, (index+1));

       /* reconfigure the layer1 position  without Reloading*/
       HAL_LTDC_SetWindowPosition_NoReload(&hltdc, Xpos1, Ypos1, 0);
       /* reconfigure the layer2 position  without Reloading*/
       HAL_LTDC_SetWindowPosition_NoReload(&hltdc, Xpos2, Ypos2, 1);
       /*Ask for LTDC reload within next vertical blanking*/
       ReloadFlag = 0;
       HAL_LTDC_Reload(&hltdc,LTDC_RELOAD_VERTICAL_BLANKING);

      while(ReloadFlag == 0)
      {
        /* wait till reload takes effect (in the next vertical blanking period) */
      }
    }
    osDelay(500);

    for (index = 0; index < 50; index++)
    {
      /* calculate new picture position */
       PicturesPosition(&Xpos2, &Ypos2, &Xpos1, &Ypos1, (index+1));

       /* reconfigure the layer1 position  without Reloading*/
       HAL_LTDC_SetWindowPosition_NoReload(&hltdc, Xpos1, Ypos1, 0);
       /* reconfigure the layer2 position  without Reloading*/
       HAL_LTDC_SetWindowPosition_NoReload(&hltdc, Xpos2, Ypos2, 1);
       /*Ask for LTDC reload within next vertical blanking*/
       ReloadFlag = 0;
       HAL_LTDC_Reload(&hltdc,LTDC_RELOAD_VERTICAL_BLANKING);

      while(ReloadFlag == 0)
      {
      	/* wait till reload takes effect (in the next vertical blanking period) */
      }
    }
    osDelay(500);
  }
  /* USER CODE END 5 */
}

/* MPU Configuration */

void MPU_Config(void)
{
  MPU_Region_InitTypeDef MPU_InitStruct = {0};

  /* Disables the MPU */
  HAL_MPU_Disable();
  /** Initializes and configures the Region and the memory to be protected
  */
  MPU_InitStruct.Enable = MPU_REGION_ENABLE;
  MPU_InitStruct.Number = MPU_REGION_NUMBER0;
  MPU_InitStruct.BaseAddress = 0xD0000000;
  MPU_InitStruct.Size = MPU_REGION_SIZE_32MB;
  MPU_InitStruct.SubRegionDisable = 0x0;
  MPU_InitStruct.TypeExtField = MPU_TEX_LEVEL0;
  MPU_InitStruct.AccessPermission = MPU_REGION_FULL_ACCESS;
  MPU_InitStruct.DisableExec = MPU_INSTRUCTION_ACCESS_ENABLE;
  MPU_InitStruct.IsShareable = MPU_ACCESS_NOT_SHAREABLE;
  MPU_InitStruct.IsCacheable = MPU_ACCESS_CACHEABLE;
  MPU_InitStruct.IsBufferable = MPU_ACCESS_NOT_BUFFERABLE;

  HAL_MPU_ConfigRegion(&MPU_InitStruct);
  /* Enables the MPU */
  HAL_MPU_Enable(MPU_PRIVILEGED_DEFAULT);

}
void HAL_TIM_PeriodElapsedCallback(TIM_HandleTypeDef *htim)
{
  if (htim->Instance == TIM6) {
    HAL_IncTick();
  }
}

void Error_Handler(void)
{
  /* USER CODE BEGIN Error_Handler_Debug */
  /* User can add his own implementation to report the HAL error return state */
  __disable_irq();
  while (1)
  {
  	HAL_GPIO_TogglePin(LD2_GPIO_Port, LD2_Pin);
  	HAL_Delay(500);
  }
  /* USER CODE END Error_Handler_Debug */
}

/************************ (C) COPYRIGHT STMicroelectronics *****END OF FILE****/
